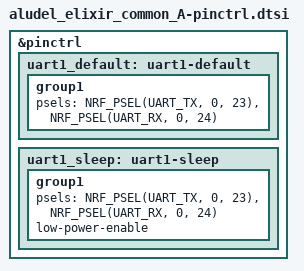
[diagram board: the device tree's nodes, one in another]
/*
 * Copyright (c) 2024 Golioth, Inc.
 *
 * SPDX-License-Identifier: Apache-2.0
 */

/* The onboard SPI NOR Flash is not enabled in Rev A */

&pinctrl {
	/* UART pins connected to the mikroBUS headers */
	uart1_default: uart1-default {
		group1 {
			psels = <NRF_PSEL(UART_TX, 0, 23)>,
				<NRF_PSEL(UART_RX, 0, 24)>;
		};
	};

	uart1_sleep: uart1-sleep {
		group1 {
			psels = <NRF_PSEL(UART_TX, 0, 23)>,
				<NRF_PSEL(UART_RX, 0, 24)>;
			low-power-enable;
		};
	};
};
